# S32K322_M7 register map
Vendor: NXP Semiconductors; File version: 1.0
CPU: CM7 r0p1, little endian, MPU, FPU, VTOR, 4 interrupt priority bits
Registers are 32-bit, read-write, reset 0x0 unless marked. A register's access mark holds for its fields unless they carry their own. Offsets are from the block's base; [hi:lo] are bit positions; {n}, {i} and the like mark numbered series; 'fields as' and 'values as' point back to an identical list.

## LPUART_0 — LPUART
Base 0x40328000
Same registers: LPUART_1 0x4032C000
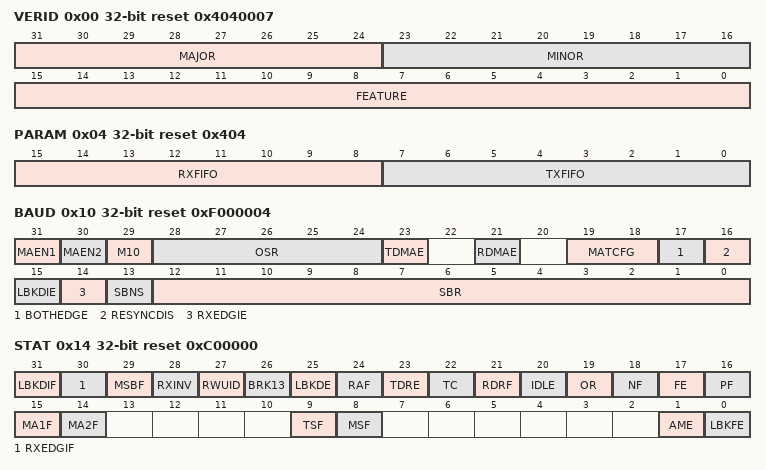
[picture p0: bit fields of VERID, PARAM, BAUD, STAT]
0x00 VERID ro reset 0x4040007 — Version ID Register
  [31:24] MAJOR — Major Version Number
  [23:16] MINOR — Minor Version Number
  [15:0] FEATURE — Feature Identification Number
    1=STANDARD (Standard feature set.); 3=MODEM (Standard feature set with MODEM/IrDA support.); 7=MODEM_IDLE (Enhanced feature set with full MODEM, IrDA and enhanced idle detection.)
0x04 PARAM ro reset 0x404 — Parameter Register
  [15:8] RXFIFO — Receive FIFO Size
  [7:0] TXFIFO — Transmit FIFO Size
0x08 GLOBAL — LPUART Global Register
  [1] RST — Software Reset
    0=NO_EFFECT (Module is not reset.); 1=RESET (Module is reset.)
0x0C PINCFG — LPUART Pin Configuration Register
  [1:0] TRGSEL — Trigger Select
    0=DISABLED (Input trigger is disabled.); 1=TRG_RXD (Input trigger is used instead of RXD pin input.); 2=TRG_CTS (Input trigger is used instead of CTS_B pin input.); 3=TRG_TXD (Input trigger is used to modulate the TXD pin output. The TXD pin output (after TXINV configuration) is internally ANDed with the input trigger.)
0x10 BAUD reset 0xF000004 — LPUART Baud Rate Register
  [31] MAEN1 — Match Address Mode Enable 1
    0=DISABLED (Normal operation.); 1=ENABLED (Enables automatic address matching or data matching mode for MATCH[MA1].)
  [30] MAEN2 — Match Address Mode Enable 2
    0=DISABLED (Normal operation.); 1=ENABLED (Enables automatic address matching or data matching mode for MATCH[MA2].)
  [29] M10 — 10-bit Mode select
    0=DISABLED (Receiver and transmitter use 7-bit to 9-bit data characters.); 1=ENABLED (Receiver and transmitter use 10-bit data characters.)
  [28:24] OSR — Oversampling Ratio
    0=DEFAULT (Writing 0 to this field results in an oversampling ratio of 16); {v}=Oversampling ratio of {v+1}, requires BOTHEDGE to be set (v=3..6); {v}=Oversampling ratio of {v+1} (v=7..31)
  [23] TDMAE — Transmitter DMA Enable
    0=DISABLED (DMA request disabled.); 1=ENABLED (DMA request enabled.)
  [21] RDMAE — Receiver Full DMA Enable
    values as TDMAE
  [19:18] MATCFG — Match Configuration
    0=ADDR_MATCH (Address Match Wakeup); 1=IDLE_MATCH (Idle Match Wakeup); 2=ONOFF_MATCH (Match On and Match Off); 3=RWU_MATCH (Enables RWU on Data Match and Match On/Off for transmitter CTS input)
  [17] BOTHEDGE — Both Edge Sampling
    0=DISABLED (Receiver samples input data using the rising edge of the baud rate clock.); 1=ENABLED (Receiver samples input data using the rising and falling edge of the baud rate clock.)
  [16] RESYNCDIS — Resynchronization Disable
    0=RESYNC (Resynchronization during received data word is supported.); 1=NO_RESYNC (Resynchronization during received data word is disabled.)
  [15] LBKDIE — LIN Break Detect Interrupt Enable
    0=DISABLE (Hardware interrupts from STAT[LBKDIF] flag are disabled (use polling).); 1=ENABLE (Hardware interrupt is requested when STAT[LBKDIF] flag is 1.)
  [14] RXEDGIE — RX Input Active Edge Interrupt Enable
    0=DISABLE (Hardware interrupts from STAT[RXEDGIF] are disabled.); 1=ENABLE (Hardware interrupt is requested when STAT[RXEDGIF] flag is 1.)
  [13] SBNS — Stop Bit Number Select
    0=ONE (One stop bit.); 1=TWO (Two stop bits.)
  [12:0] SBR — Baud Rate Modulo Divisor.
0x14 STAT reset 0xC00000 — LPUART Status Register
  [31] LBKDIF write-1-clears — LIN Break Detect Interrupt Flag
    0=NOT_DETECTED (No LIN break character has been detected.); 1=DETECTED (LIN break character has been detected.)
  [30] RXEDGIF write-1-clears — RXD Pin Active Edge Interrupt Flag
    0=NO_EDGE (No active edge on the receive pin has occurred.); 1=EDGE (An active edge on the receive pin has occurred.)
  [29] MSBF — MSB First
    0=LSB_FIRST (LSB (bit0) is the first bit that is transmitted following the start bit. Further, the first bit received after the start bit is identified as bit0.); 1=MSB_FIRST (MSB (identified as bit9, bit8, bit7 or bit6) is the first bit that is transmitted following the start bit depending on the setting of CTRL[M], CTRL[PE] and BAUD[M10]. .)
  [28] RXINV — Receive Data Inversion
    0=NOT_INVERTED (Receive data not inverted.); 1=INVERTED (Receive data inverted.)
  [27] RWUID — Receive Wake Up Idle Detect
    0=IDLE_NOTSET (During receive standby state (RWU = 1), the IDLE bit does not get set upon detection of an idle character. During address match wakeup, the IDLE bit does not set when an address does not match.); 1=IDLE_SET (During receive standby state (RWU = 1), the IDLE bit gets set upon detection of an idle character. During address match wakeup, the IDLE bit does set when an address does not match.)
  [26] BRK13 — Break Character Generation Length
    0=SHORT (Break character is transmitted with length of 9 to 13 bit times.); 1=LONG (Break character is transmitted with length of 12 to 15 bit times.)
  [25] LBKDE — LIN Break Detection Enable
    0=DISABLED (LIN break detect is disabled, normal break character can be detected.); 1=ENABLED (LIN break detect is enabled. LIN break character is detected at length of 11 bit times (if M = 0) or 12 (if M = 1) or 13 (M10 = 1).)
  [24] RAF ro — Receiver Active Flag
    0=IDLE (LPUART receiver idle waiting for a start bit.); 1=ACTIVE (LPUART receiver active (RXD input not idle).)
  [23] TDRE ro — Transmit Data Register Empty Flag
    0=TXDATA (Transmit FIFO level is greater than watermark.); 1=NO_TXDATA (Transmit FIFO level is equal or less than watermark.)
  [22] TC ro — Transmission Complete Flag
    0=ACTIVE (Transmitter active (sending data, a preamble, or a break).); 1=COMPLETE (Transmitter idle (transmission activity complete).)
  [21] RDRF ro — Receive Data Register Full Flag
    0=NO_RXDATA (Receive FIFO level is less than watermark.); 1=RXDATA (Receive FIFO level is equal or greater than watermark.)
  [20] IDLE write-1-clears — Idle Line Flag
    0=NOIDLE (No idle line detected.); 1=IDLE (Idle line is detected.)
  [19] OR write-1-clears — Receiver Overrun Flag
    0=NO_OVERRUN; 1=OVERRUN (Receive overrun (new LPUART data lost).)
  [18] NF write-1-clears — Noise Flag
    0=NONOISE (No noise detected.); 1=NOISE (Noise detected in the received character in the DATA register.)
  [17] FE write-1-clears — Framing Error Flag
    0=NOERROR (No framing error detected. This does not guarantee the framing is correct.); 1=ERROR (Framing error.)
  [16] PF write-1-clears — Parity Error Flag
    0=NOPARITY (No parity error.); 1=PARITY (Parity error.)
  [15] MA1F write-1-clears — Match 1 Flag
    0=NOMATCH (Received data is not equal to MA1); 1=MATCH (Received data is equal to MA1)
  [14] MA2F write-1-clears — Match 2 Flag
    0=NOMATCH (Received data is not equal to MA2); 1=MATCH (Received data is equal to MA2)
  [9] TSF ro — Timeout Status Flag
    0=NOFLAG (Flag is clear); 1=FLAG (Flag is set)
  [8] MSF ro — MODEM Status Flag
    0=NOFLAG (Flag is clear); 1=FLAG (Flag is set)
  [1] AME — Address Mark Enable
    0=DISABLED (Address mark in character is MSB.); 1=ENABLED (Address mark in character is last bit before stop bit (or parity bit when enabled) and stored in DATA register at MSB (or MSB-1 when parity bit enabled).)
  [0] LBKFE — LIN Break Flag Enable
    0=DISABLED (LIN break detect is disabled.); 1=ENABLED (LIN break detect is enabled. LIN break character is detected at length of 11 bit times (if M = 0) or 12 (if M = 1) or 13 (M10 = 1).)
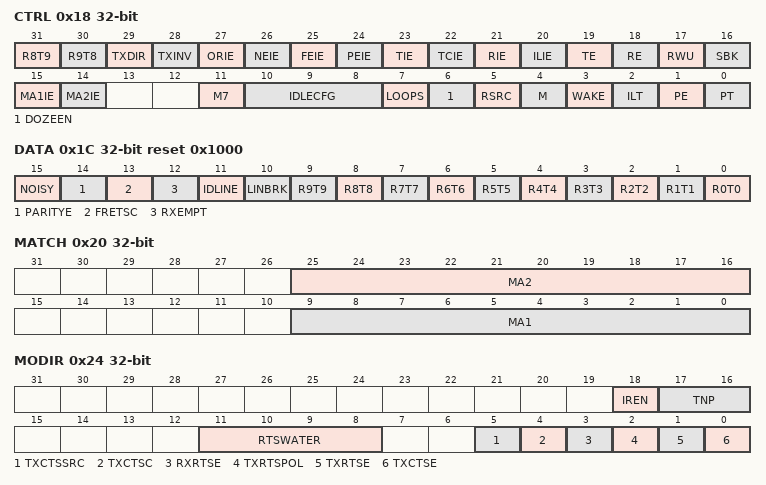
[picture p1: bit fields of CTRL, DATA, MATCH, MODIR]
0x18 CTRL — LPUART Control Register
  [31] R8T9 — Receive Bit 8 / Transmit Bit 9
  [30] R9T8 — Receive Bit 9 / Transmit Bit 8
  [29] TXDIR — TXD Pin Direction in Single-Wire Mode
    0=TX_INPUT (TXD pin is an input in single-wire mode.); 1=TX_OUTPUT (TXD pin is an output in single-wire mode.)
  [28] TXINV — Transmit Data Inversion
    0=NOT_INVERTED (Transmit data not inverted.); 1=INVERTED (Transmit data inverted.)
  [27] ORIE — Overrun Interrupt Enable
    0=DISABLED (OR interrupts disabled; use polling.); 1=ENABLED (Hardware interrupt is requested when OR is set.)
  [26] NEIE — Noise Error Interrupt Enable
    0=DISABLED (NF interrupts disabled; use polling.); 1=ENABLED (Hardware interrupt is requested when NF is set.)
  [25] FEIE — Framing Error Interrupt Enable
    0=DISABLED (FE interrupts disabled; use polling.); 1=ENABLED (Hardware interrupt is requested when FE is set.)
  [24] PEIE — Parity Error Interrupt Enable
    0=DISABLED (PF interrupts disabled; use polling).); 1=ENABLED (Hardware interrupt is requested when PF is set.)
  [23] TIE — Transmit Interrupt Enable
    0=DISABLED (Hardware interrupts from TDRE disabled.); 1=ENABLED (Hardware interrupt is requested when TDRE flag is 1.)
  [22] TCIE — Transmission Complete Interrupt Enable for
    0=DISABLED (Hardware interrupts from TC disabled.); 1=ENABLED (Hardware interrupt is requested when TC flag is 1.)
  [21] RIE — Receiver Interrupt Enable
    0=DISABLED (Hardware interrupts from RDRF disabled.); 1=ENABLED (Hardware interrupt is requested when RDRF flag is 1.)
  [20] ILIE — Idle Line Interrupt Enable
    0=DISABLED (Hardware interrupts from IDLE disabled; use polling.); 1=ENABLED (Hardware interrupt is requested when IDLE flag is 1.)
  [19] TE — Transmitter Enable
    0=DISABLED (Transmitter disabled.); 1=ENABLED (Transmitter enabled.)
  [18] RE — Receiver Enable
    0=DISABLED (Receiver disabled.); 1=ENABLED (Receiver enabled.)
  [17] RWU — Receiver Wakeup Control
    0=NO_EFFECT (Normal receiver operation.); 1=RX_WAKEUP (LPUART receiver in standby waiting for wakeup condition.)
  [16] SBK — Send Break
    0=NO_EFFECT (Normal transmitter operation.); 1=TX_BREAK (Queue break character(s) to be sent.)
  [15] MA1IE — Match 1 Interrupt Enable
    0=DISABLED (MA1F interrupt disabled); 1=ENABLED (MA1F interrupt enabled)
  [14] MA2IE — Match 2 Interrupt Enable
    0=DISABLED (MA2F interrupt disabled); 1=ENABLED (MA2F interrupt enabled)
  [11] M7 — 7-Bit Mode Select
    0=NO_EFFECT (Receiver and transmitter use 8-bit to 10-bit data characters.); 1=DATA7 (Receiver and transmitter use 7-bit data characters.)
  [10:8] IDLECFG — Idle Configuration
    0=IDLE_1 (1 idle character); 1=IDLE_2 (2 idle characters); 2=IDLE_4 (4 idle characters); 3=IDLE_8 (8 idle characters); 4=IDLE_16 (16 idle characters); 5=IDLE_32 (32 idle characters); 6=IDLE_64 (64 idle characters); 7=IDLE_128 (128 idle characters)
  [7] LOOPS — Loop Mode Select
    0=NOFFECT (Normal operation - RXD and TXD use separate pins.); 1=LOOPBACK (Loop mode or single-wire mode where transmitter outputs are internally connected to receiver input (see RSRC bit).)
  [6] DOZEEN — Doze Enable
    0=ENABLED (LPUART is enabled in Doze mode.); 1=DISABLED (LPUART is disabled in Doze mode , but remains active when not in Doze mode .)
  [5] RSRC — Receiver Source Select
    0=NO_EFFECT (Provided LOOPS is set, RSRC is cleared, selects internal loop back mode and the LPUART does not use the RXD pin. The CTS_B pin is not used and internally driven by the RTS_B output. The DSR_B pin is not used and internally driven by the DTR_B output.); 1=ONEWIRE (Single-wire LPUART mode where the TXD pin is connected to the transmitter output and receiver input.)
  [4] M — 9-Bit or 8-Bit Mode Select
    0=DATA8 (Receiver and transmitter use 8-bit data characters.); 1=DATA9 (Receiver and transmitter use 9-bit data characters.)
  [3] WAKE — Receiver Wakeup Method Select
    0=IDLE (Configures RWU for idle-line wakeup.); 1=MARK (Configures RWU with address-mark wakeup.)
  [2] ILT — Idle Line Type Select
    0=FROM_START (Idle character bit count starts after start bit.); 1=FROM_STOP (Idle character bit count starts after stop bit.)
  [1] PE — Parity Enable
    0=DISABLED (No hardware parity generation or checking.); 1=ENABLED (Parity enabled.)
  [0] PT — Parity Type
    0=EVEN (Even parity.); 1=ODD (Odd parity.)
0x1C DATA reset 0x1000 — LPUART Data Register
  [15] NOISY ro — Noisy Data Received
    0=NO_NOISE (The dataword is received without noise.); 1=NOISE (The data is received with noise.)
  [14] PARITYE ro — Parity Error
    0=NO_PARITY (The dataword is received without a parity error.); 1=PARITY (The dataword is received with a parity error.)
  [13] FRETSC — Frame Error / Transmit Special Character
    0=NO_ERROR (The dataword is received without a frame error on read, or transmit a normal character on write.); 1=ERROR (The dataword is received with a frame error, or transmit an idle or break character on transmit.)
  [12] RXEMPT ro — Receive Buffer Empty
    0=NOT_EMPTY (Receive buffer contains valid data.); 1=EMPTY (Receive buffer is empty, data returned on read is not valid.)
  [11] IDLINE ro — Idle Line
    0=NO_IDLE (Receiver was not idle before receiving this character.); 1=IDLE (Receiver was idle before receiving this character.)
  [10] LINBRK ro — LIN Break
    0=NO_BREAK (Receiver did not detect LIN break before this character, or LIN break detect circuitry disabled.); 1=BREAK (Receiver detected a LIN break before receiving this character.)
  [n] R{n}T{n} (n=0..9)
0x20 MATCH — LPUART Match Address Register
  [25:16] MA2 — Match Address 2
  [9:0] MA1 — Match Address 1
0x24 MODIR — LPUART Modem IrDA Register
  [18] IREN — Infrared enable
    0=DISABLED (IR disabled.); 1=ENABLED (IR enabled.)
  [17:16] TNP — Transmitter narrow pulse
    0=ONE_SAMPLE (1/OSR.); 1=TWO_SAMPLE (2/OSR.); 2=THREE_SAMPLE (3/OSR.); 3=FOUR_SAMPLE (4/OSR.)
  [11:8] RTSWATER — Receive RTS Configuration
  [5] TXCTSSRC — Transmit CTS Source
    0=CTS (CTS input is the CTS_B pin.); 1=MATCH (CTS input is an internal connection to the receiver address match result.)
  [4] TXCTSC — Transmit CTS Configuration
    0=START (CTS input is sampled at the start of each character.); 1=IDLE (CTS input is sampled when the transmitter is idle.)
  [3] RXRTSE — Receiver request-to-send enable
    0=DISABLED (The receiver has no effect on RTS.); 1=ENABLED (RTS is deasserted if the receiver data register is full or a start bit has been detected that would cause the receiver data register to become full. RTS is asserted if the receiver data register is not full and has not detected a start bit that would cause the receiver data register to become full.)
  [2] TXRTSPOL — Transmitter request-to-send polarity
    0=LOW (Transmitter RTS is active low.); 1=HIGH (Transmitter RTS is active high.)
  [1] TXRTSE — Transmitter request-to-send enable
    0=DISABLED (The transmitter has no effect on RTS.); 1=ENABLED (When a character is placed into an empty transmit shift register, RTS asserts one bit time before the start bit is transmitted. RTS deasserts one bit time after all characters in the transmitter FIFO and shift register are completely sent, including the last stop bit.)
  [0] TXCTSE — Transmitter clear-to-send enable
    0=DISABLED (CTS has no effect on the transmitter.); 1=ENABLED (Enables clear-to-send operation. The transmitter checks the state of CTS each time it is ready to send a character. If CTS is asserted, the character is sent. If CTS is deasserted, the signal TXD remains in the mark state and transmission is delayed until CTS is asserted. Changes in CTS as a character is being sent do not affect its transmission.)
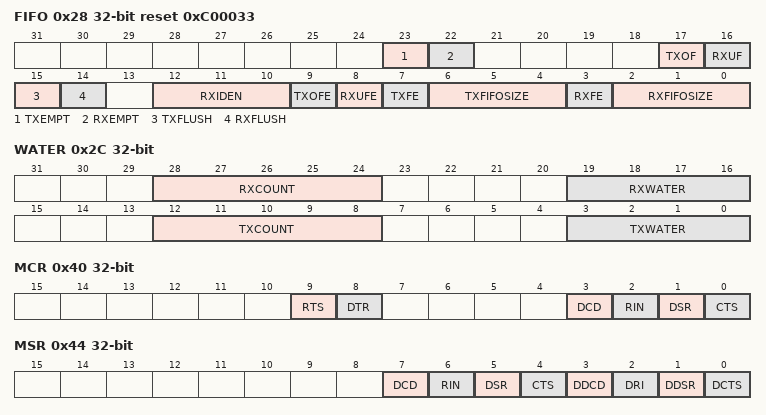
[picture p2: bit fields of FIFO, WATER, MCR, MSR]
0x28 FIFO reset 0xC00033 — LPUART FIFO Register
  [23] TXEMPT ro — Transmit FIFO/Buffer Empty
    0=NOT_EMPTY (Transmit buffer is not empty.); 1=EMPTY (Transmit buffer is empty.)
  [22] RXEMPT ro — Receive FIFO/Buffer Empty
    0=NOT_EMPTY (Receive buffer is not empty.); 1=EMPTY (Receive buffer is empty.)
  [17] TXOF write-1-clears — Transmitter FIFO Overflow Flag
    0=NO_OVERFLOW (No transmit FIFO overflow has occurred since the last time the flag was cleared.); 1=OVERFLOW (At least one transmit FIFO overflow has occurred since the last time the flag was cleared.)
  [16] RXUF write-1-clears — Receiver FIFO Underflow Flag
    0=NO_UNDERFLOW (No receive FIFO underflow has occurred since the last time the flag was cleared.); 1=UNDERFLOW (At least one receive FIFO underflow has occurred since the last time the flag was cleared.)
  [15] TXFLUSH — Transmit FIFO Flush
    0=NO_EFFECT (No flush operation occurs.); 1=TXFIFO_RST (All data in the transmit FIFO is cleared out.)
  [14] RXFLUSH — Receive FIFO Flush
    0=NO_EFFECT (No flush operation occurs.); 1=RXFIFO_RST (All data in the receive FIFO/buffer is cleared out.)
  [12:10] RXIDEN — Receiver Idle Empty Enable
    0=DISABLED (Disable RDRF assertion due to partially filled FIFO when receiver is idle.); 1=IDLE_1 (Enable RDRF assertion due to partially filled FIFO when receiver is idle for 1 character.); 2=IDLE_2 (Enable RDRF assertion due to partially filled FIFO when receiver is idle for 2 characters.); 3=IDLE_4 (Enable RDRF assertion due to partially filled FIFO when receiver is idle for 4 characters.); 4=IDLE_8 (Enable RDRF assertion due to partially filled FIFO when receiver is idle for 8 characters.); 5=IDLE_16 (Enable RDRF assertion due to partially filled FIFO when receiver is idle for 16 characters.); 6=IDLE_32 (Enable RDRF assertion due to partially filled FIFO when receiver is idle for 32 characters.); 7=IDLE_64 (Enable RDRF assertion due to partially filled FIFO when receiver is idle for 64 characters.)
  [9] TXOFE — Transmit FIFO Overflow Interrupt Enable
    0=DISABLED (TXOF flag does not generate an interrupt to the host.); 1=ENABLED (TXOF flag generates an interrupt to the host.)
  [8] RXUFE — Receive FIFO Underflow Interrupt Enable
    0=DISABLED (RXUF flag does not generate an interrupt to the host.); 1=ENABLED (RXUF flag generates an interrupt to the host.)
  [7] TXFE — Transmit FIFO Enable
    0=DISABLED (Transmit FIFO is not enabled. Buffer depth is 1.); 1=ENABLED (Transmit FIFO is enabled. Buffer depth is indicated by TXFIFOSIZE.)
  [6:4] TXFIFOSIZE ro — Transmit FIFO Buffer Depth
    0=FIFO_1 (Transmit FIFO/Buffer depth = 1 dataword.); 1=FIFO_4 (Transmit FIFO/Buffer depth = 4 datawords.); 2=FIFO_8 (Transmit FIFO/Buffer depth = 8 datawords.); 3=FIFO_16 (Transmit FIFO/Buffer depth = 16 datawords.); 4=FIFO_32 (Transmit FIFO/Buffer depth = 32 datawords.); 5=FIFO_64 (Transmit FIFO/Buffer depth = 64 datawords.); 6=FIFO_128 (Transmit FIFO/Buffer depth = 128 datawords.); 7=FIFO_256 (Transmit FIFO/Buffer depth = 256 datawords)
  [3] RXFE — Receive FIFO Enable
    0=DISABLED (Receive FIFO is not enabled. Buffer depth is 1.); 1=ENABLED (Receive FIFO is enabled. Buffer depth is indicted by RXFIFOSIZE.)
  [2:0] RXFIFOSIZE ro — Receive FIFO Buffer Depth
    0=FIFO_1 (Receive FIFO/Buffer depth = 1 dataword.); 1=FIFO_4 (Receive FIFO/Buffer depth = 4 datawords.); 2=FIFO_8 (Receive FIFO/Buffer depth = 8 datawords.); 3=FIFO_16 (Receive FIFO/Buffer depth = 16 datawords.); 4=FIFO_32 (Receive FIFO/Buffer depth = 32 datawords.); 5=FIFO_64 (Receive FIFO/Buffer depth = 64 datawords.); 6=FIFO_128 (Receive FIFO/Buffer depth = 128 datawords.); 7=FIFO_256 (Receive FIFO/Buffer depth = 256 datawords.)
0x2C WATER — LPUART Watermark Register
  [28:24] RXCOUNT ro — Receive Counter
  [19:16] RXWATER — Receive Watermark
  [12:8] TXCOUNT ro — Transmit Counter
  [3:0] TXWATER — Transmit Watermark
0x30 DATARO ro reset 0x1000 — Data read-only Register
  [15:0] DATA — Receive Data
0x40 MCR — MODEM Control Register
  [9] RTS — Request To Send
    0=LOGIC_ONE (Default state of RTS_B is logic one); 1=LOGIC_ZERO (Default state of RTS_B is logic zero)
  [8] DTR — Data Terminal Ready
    0=LOGIC_ONE (Default state of DTR_B is logic one); 1=LOGIC_ZERO (Default state of DTR_B is logic zero)
  [3] DCD — Data Carrier Detect
    0=DISABLED (The DCD_B interrupt disabled); 1=ENABLED (The DCD_B interrupt enabled)
  [2] RIN — Ring Indicator
    0=DISABLED (The RIN_B interrupt disabled); 1=ENABLED (The RIN_B interrupt enabled)
  [1] DSR — Data Set Ready
    0=DISABLED (The DSR_B interrupt disabled); 1=ENABLED (The DSR_B interrupt enabled)
  [0] CTS — Clear To Send
    0=DISABLED (The CTS_B interrupt disabled); 1=ENABLED (The CTS_B interrupt enabled)
0x44 MSR — MODEM Status Register
  [7] DCD ro — Data Carrier Detect
    0=LOGIC_ONE (The DCD_B pin is logic one); 1=LOGIC_ZERO (The DCD_B pin is logic zero)
  [6] RIN ro — Ring Indicator
    0=LOGIC_ONE (The RIN_B pin is logic one); 1=LOGIC_ZERO (The RIN_B pin is logic zero)
  [5] DSR ro — Data Set Ready
    0=LOGIC_ONE (The DSR_B pin is logic one); 1=LOGIC_ZERO (The DSR_B pin is logic zero)
  [4] CTS ro — Clear To Send
    0=LOGIC_ONE (The CTS_B pin is logic one); 1=LOGIC_ZERO (The CTS_B pin is logic zero)
  [3] DDCD write-1-clears — Delta Data Carrier Detect
    0=NO_CHANGE (The DCD_B pin has not changed state); 1=CHANGE (The DCD_B pin has changed state)
  [2] DRI write-1-clears — Delta Ring Indicator
    0=NO_CHANGE (The RIN_B pin has not changed state); 1=CHANGE (The RIN_B pin has changed state)
  [1] DDSR write-1-clears — Delta Data Set Ready
    0=NO_CHANGE (The DSR_B pin has not changed state); 1=CHANGE (The DSR_B pin has changed state)
  [0] DCTS write-1-clears — Delta Clear To Send
    0=NO_CHANGE (The CTS_B pin has not changed state); 1=CHANGE (The CTS_B pin has changed state)
0x48 REIR — Receiver Extended Idle Register
  [13:0] IDTIME — Idle Time
0x4C TEIR — Transmitter Extended Idle Register
  [13:0] IDTIME — Idle Time
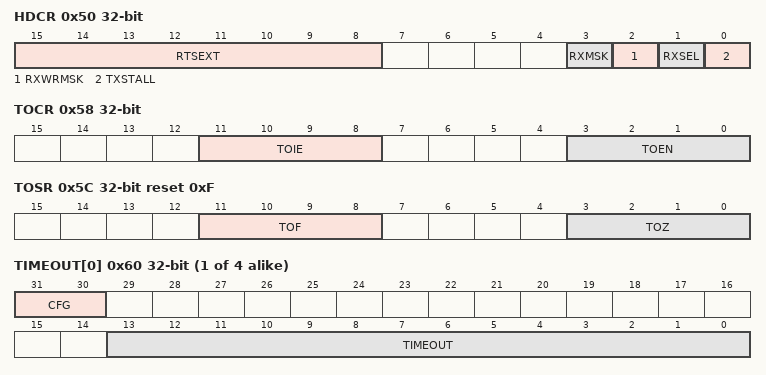
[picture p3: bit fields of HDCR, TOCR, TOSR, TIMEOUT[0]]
0x50 HDCR — Half Duplex Control Register
  [15:8] RTSEXT — RTS Extended
  [3] RXMSK — Receive Mask
    0=NO_EFFECT (Receive data pin is not masked by the transmitter RTS_B); 1=TX_RTS (Receive data pin is masked by the transmitter RTS_B)
  [2] RXWRMSK — Receive FIFO Write Mask
    0=NO_EFFECT (Receive FIFO writes are not masked); 1=TX_RTS (Receive FIFO writes are masked by the transmitter RTS_B)
  [1] RXSEL — Receive Select
    0=PIN_RXD (Receive data pin is RXD); 1=PIN_TXD (Receive data pin is TXD)
  [0] TXSTALL — Transmit Stall
    0=NO_EFFECT; 1=RX_ACTIVE (Transmitter will not become busy when receiver is active)
0x58 TOCR — Timeout Control Register
  [11:8] TOIE — Timeout Interrupt Enable
  [3:0] TOEN — Timeout Enable
0x5C TOSR reset 0xF — Timeout Status Register
  [11:8] TOF write-1-clears — Timeout Flag
  [3:0] TOZ ro — Timeout Zero
{0x60+4i} TIMEOUT[{i}] (i=0..3) — Timeout N Register
  [31:30] CFG — Idle Configuration
    0=CNT_CHAR (Flag sets after TIMEOUT characters are received); 1=CNT_IDLE (Flag sets when idle for TIMEOUT bit clocks); 2=CNT_BUSY_IDLE (Flag sets when idle for TIMEOUT bit clocks following the next character); 3=CNT_CHAR_IDLE (Flag sets when idle for at least TIMEOUT bit clocks, but new character is detected before extended idle timeout is reached)
  [13:0] TIMEOUT — Timeout Value
{0x200+4i} TCBR[{i}] (i=0..127) wo — Transmit Command Burst Register
  [15:0] DATA
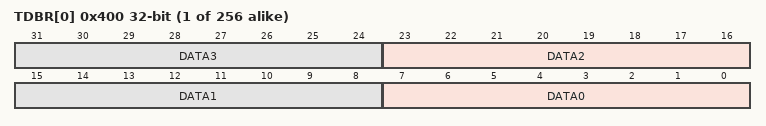
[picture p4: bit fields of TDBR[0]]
{0x400+4i} TDBR[{i}] (i=0..255) wo — Transmit Data Burst Register
  [8n+7:8n] DATA{n} (n=0..3) — Data
